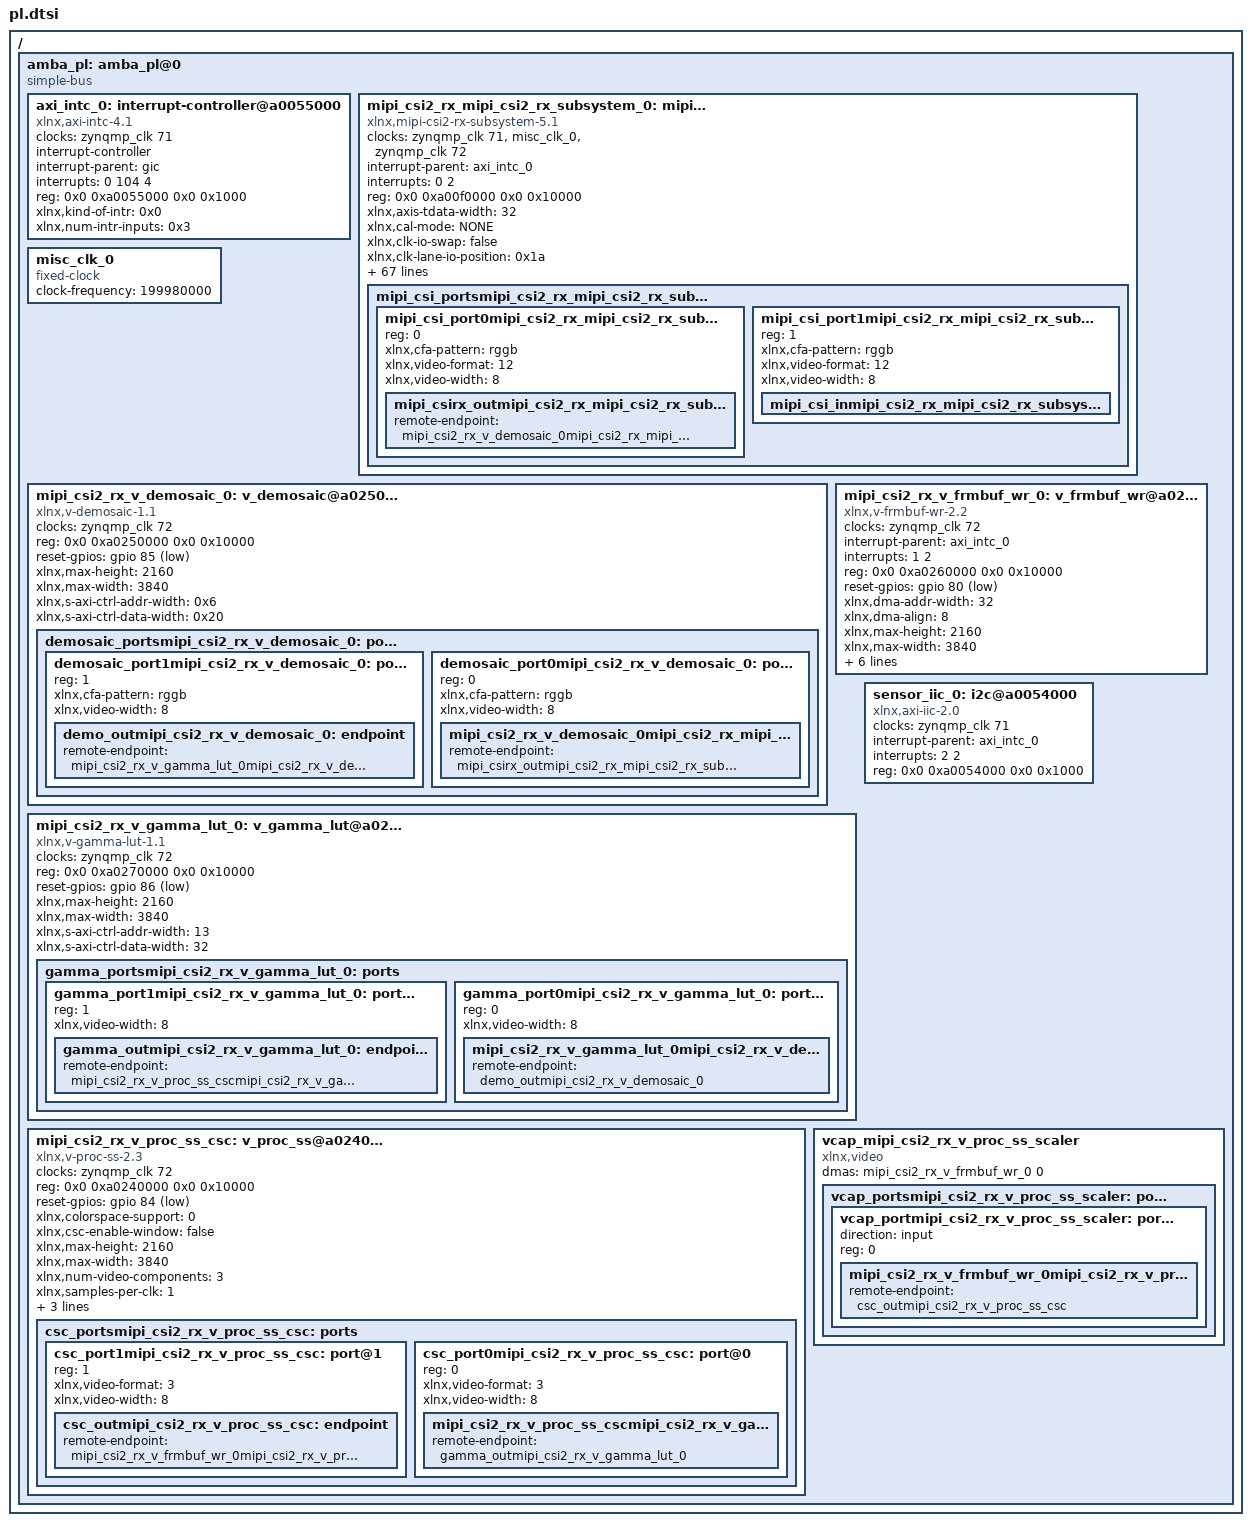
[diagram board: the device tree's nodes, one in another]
/*
 * CAUTION: This file is automatically generated by Xilinx.
 * Version: XSCT 2020.2
 * Today is: Wed Feb  9 18:55:34 2022
 */


/ {
	amba_pl: amba_pl@0 {
		#address-cells = <2>;
		#size-cells = <2>;
		compatible = "simple-bus";
		ranges ;
		axi_intc_0: interrupt-controller@a0055000 {
			#interrupt-cells = <2>;
			clock-names = "s_axi_aclk";
			clocks = <&zynqmp_clk 71>;
			compatible = "xlnx,axi-intc-4.1", "xlnx,xps-intc-1.00.a";
			interrupt-controller ;
			interrupt-names = "irq";
			interrupt-parent = <&gic>;
			interrupts = <0 104 4>;
			reg = <0x0 0xa0055000 0x0 0x1000>;
			xlnx,kind-of-intr = <0x0>;
			xlnx,num-intr-inputs = <0x3>;
		};
		mipi_csi2_rx_mipi_csi2_rx_subsystem_0: mipi_csi2_rx_subsystem@a00f0000 {
			clock-names = "lite_aclk", "dphy_clk_200M", "video_aclk";
			clocks = <&zynqmp_clk 71>, <&misc_clk_0>, <&zynqmp_clk 72>;
			compatible = "xlnx,mipi-csi2-rx-subsystem-5.1";
			interrupt-names = "csirxss_csi_irq";
			interrupt-parent = <&axi_intc_0>;
			interrupts = <0 2>;
			reg = <0x0 0xa00f0000 0x0 0x10000>;
			xlnx,axis-tdata-width = <32>;
			xlnx,cal-mode = "NONE";
			xlnx,clk-io-swap = "false";
			xlnx,clk-lane-io-position = <0x1a>;
			xlnx,clk-lp-io-swap = "false";
			xlnx,csi-en-activelanes = "true";
			xlnx,csi-en-crc = "true";
			xlnx,csi-filter-userdatatype = "true";
			xlnx,csi-opt1-regs = "false";
			xlnx,csi-pxl-format = "RAW10";
			xlnx,csi2rx-dbg = <0x0>;
			xlnx,data-lane0-io-position = <0x2d>;
			xlnx,data-lane1-io-position = <0x20>;
			xlnx,data-lane2-io-position = <0x11>;
			xlnx,data-lane3-io-position = <0x29>;
			xlnx,dl0-io-swap = "false";
			xlnx,dl0-lp-io-swap = "false";
			xlnx,dl1-io-swap = "false";
			xlnx,dl1-lp-io-swap = "false";
			xlnx,dl2-io-swap = "false";
			xlnx,dl2-lp-io-swap = "false";
			xlnx,dl3-io-swap = "false";
			xlnx,dl3-lp-io-swap = "false";
			xlnx,dphy-lanes = <0x4>;
			xlnx,dphy-mode = "SLAVE";
			xlnx,en-7s-linerate-check = "false";
			xlnx,en-active-lanes ;
			xlnx,en-bg0-pin0 = "false";
			xlnx,en-bg0-pin6 = "false";
			xlnx,en-bg1-pin0 = "true";
			xlnx,en-bg1-pin6 = "false";
			xlnx,en-bg2-pin0 = "false";
			xlnx,en-bg2-pin6 = "false";
			xlnx,en-bg3-pin0 = "true";
			xlnx,en-bg3-pin6 = "false";
			xlnx,en-clk300m = "false";
			xlnx,en-cnts-byte-clk = "false";
			xlnx,en-csi-v2-0 = "false";
			xlnx,en-exdesigns = "false";
			xlnx,en-ext-tap = "false";
			xlnx,en-timeout-regs = "false";
			xlnx,en-vcx = "false";
			xlnx,esc-timeout = <0x6400>;
			xlnx,exdes-board = "ZCU102";
			xlnx,exdes-config = "MIPI_Video_Pipe_Camera_to_Display";
			xlnx,exdes-fmc = "LI-IMX274MIPI-FMC V1.0 Single Sensor";
			xlnx,exdesboard-version = "xilinx.com:vck190:part0:2.0";
			xlnx,fifo-rd-en-control = "true";
			xlnx,hs-line-rate = <0x5a0>;
			xlnx,hs-settle-ns = <0x8d>;
			xlnx,hs-timeout = <0x10005>;
			xlnx,idly-group-name = "mipi_csi2rx_idly_group";
			xlnx,idly-tap = <0x1>;
			xlnx,init = <0x186a0>;
			xlnx,int-qor-check = <0x0>;
			xlnx,is-7series = "false";
			xlnx,is-versal = "false";
			xlnx,lprx-disable-extport = <0x0>;
			xlnx,max-lanes = <4>;
			xlnx,mipi-slv-int = <0x0>;
			xlnx,ooc-vid-clk = "6.666";
			xlnx,ppc = <1>;
			xlnx,rcve-alt-deskew-seq = "false";
			xlnx,rcve-deskew-seq = "false";
			xlnx,share-idlyctrl = "false";
			xlnx,stretch-line-rate = <0xdac>;
			xlnx,vc = <4>;
			xlnx,vfb ;
			mipi_csi_portsmipi_csi2_rx_mipi_csi2_rx_subsystem_0: ports {
				#address-cells = <1>;
				#size-cells = <0>;
				mipi_csi_port0mipi_csi2_rx_mipi_csi2_rx_subsystem_0: port@0 {
					/* Fill cfa-pattern=rggb for raw data types, other fields video-format and video-width user needs to fill */
					reg = <0>;
					xlnx,cfa-pattern = "rggb";
					xlnx,video-format = <12>;
					xlnx,video-width = <8>;
					mipi_csirx_outmipi_csi2_rx_mipi_csi2_rx_subsystem_0: endpoint {
						remote-endpoint = <&mipi_csi2_rx_v_demosaic_0mipi_csi2_rx_mipi_csi2_rx_subsystem_0>;
					};
				};
				mipi_csi_port1mipi_csi2_rx_mipi_csi2_rx_subsystem_0: port@1 {
					/* Fill cfa-pattern=rggb for raw data types, other fields video-format,video-width user needs to fill */
					/* User need to add something like remote-endpoint=<&out> under the node csiss_in:endpoint */
					reg = <1>;
					xlnx,cfa-pattern = "rggb";
					xlnx,video-format = <12>;
					xlnx,video-width = <8>;
					mipi_csi_inmipi_csi2_rx_mipi_csi2_rx_subsystem_0: endpoint {
					};
				};
			};
		};
		misc_clk_0: misc_clk_0 {
			#clock-cells = <0>;
			clock-frequency = <199980000>;
			compatible = "fixed-clock";
		};
		mipi_csi2_rx_v_demosaic_0: v_demosaic@a0250000 {
			clock-names = "ap_clk";
			clocks = <&zynqmp_clk 72>;
			compatible = "xlnx,v-demosaic-1.1", "xlnx,v-demosaic";
			reg = <0x0 0xa0250000 0x0 0x10000>;
			reset-gpios = <&gpio 85 1>;
			xlnx,max-height = <2160>;
			xlnx,max-width = <3840>;
			xlnx,s-axi-ctrl-addr-width = <0x6>;
			xlnx,s-axi-ctrl-data-width = <0x20>;
			demosaic_portsmipi_csi2_rx_v_demosaic_0: ports {
				#address-cells = <1>;
				#size-cells = <0>;
				demosaic_port1mipi_csi2_rx_v_demosaic_0: port@1 {
					/* For cfa-pattern=rggb user needs to fill as per BAYER format */
					reg = <1>;
					xlnx,cfa-pattern = "rggb";
					xlnx,video-width = <8>;
					demo_outmipi_csi2_rx_v_demosaic_0: endpoint {
						remote-endpoint = <&mipi_csi2_rx_v_gamma_lut_0mipi_csi2_rx_v_demosaic_0>;
					};
				};
				demosaic_port0mipi_csi2_rx_v_demosaic_0: port@0 {
					/* For cfa-pattern=rggb user needs to fill as per BAYER format */
					reg = <0>;
					xlnx,cfa-pattern = "rggb";
					xlnx,video-width = <8>;
					mipi_csi2_rx_v_demosaic_0mipi_csi2_rx_mipi_csi2_rx_subsystem_0: endpoint {
						remote-endpoint = <&mipi_csirx_outmipi_csi2_rx_mipi_csi2_rx_subsystem_0>;
					};
				};
			};
		};
		mipi_csi2_rx_v_frmbuf_wr_0: v_frmbuf_wr@a0260000 {
			#dma-cells = <1>;
			clock-names = "ap_clk";
			clocks = <&zynqmp_clk 72>;
			compatible = "xlnx,v-frmbuf-wr-2.2", "xlnx,axi-frmbuf-wr-v2.1";
			interrupt-names = "interrupt";
			interrupt-parent = <&axi_intc_0>;
			interrupts = <1 2>;
			reg = <0x0 0xa0260000 0x0 0x10000>;
			reset-gpios = <&gpio 80 1>;
			xlnx,dma-addr-width = <32>;
			xlnx,dma-align = <8>;
			xlnx,max-height = <2160>;
			xlnx,max-width = <3840>;
			xlnx,pixels-per-clock = <1>;
			xlnx,s-axi-ctrl-addr-width = <0x7>;
			xlnx,s-axi-ctrl-data-width = <0x20>;
			xlnx,vid-formats = "bgr888", "xbgr8888", "xrgb8888", "uyvy", "y8", "vuy888", "xvuy8888", "yuyv", "nv12", "nv16";
			xlnx,video-width = <8>;
		};
		mipi_csi2_rx_v_gamma_lut_0: v_gamma_lut@a0270000 {
			clock-names = "ap_clk";
			clocks = <&zynqmp_clk 72>;
			compatible = "xlnx,v-gamma-lut-1.1", "xlnx,v-gamma-lut";
			reg = <0x0 0xa0270000 0x0 0x10000>;
			reset-gpios = <&gpio 86 1>;
			xlnx,max-height = <2160>;
			xlnx,max-width = <3840>;
			xlnx,s-axi-ctrl-addr-width = <13>;
			xlnx,s-axi-ctrl-data-width = <32>;
			gamma_portsmipi_csi2_rx_v_gamma_lut_0: ports {
				#address-cells = <1>;
				#size-cells = <0>;
				gamma_port1mipi_csi2_rx_v_gamma_lut_0: port@1 {
					reg = <1>;
					xlnx,video-width = <8>;
					gamma_outmipi_csi2_rx_v_gamma_lut_0: endpoint {
						remote-endpoint = <&mipi_csi2_rx_v_proc_ss_cscmipi_csi2_rx_v_gamma_lut_0>;
					};
				};
				gamma_port0mipi_csi2_rx_v_gamma_lut_0: port@0 {
					reg = <0>;
					xlnx,video-width = <8>;
					mipi_csi2_rx_v_gamma_lut_0mipi_csi2_rx_v_demosaic_0: endpoint {
						remote-endpoint = <&demo_outmipi_csi2_rx_v_demosaic_0>;
					};
				};
			};
		};
		mipi_csi2_rx_v_proc_ss_csc: v_proc_ss@a0240000 {
			clock-names = "aclk";
			clocks = <&zynqmp_clk 72>;
			compatible = "xlnx,v-proc-ss-2.3", "xlnx,vpss-csc", "xlnx,v-vpss-csc";
			reg = <0x0 0xa0240000 0x0 0x10000>;
			reset-gpios = <&gpio 84 1>;
			xlnx,colorspace-support = <0>;
			xlnx,csc-enable-window = "false";
			xlnx,max-height = <2160>;
			xlnx,max-width = <3840>;
			xlnx,num-video-components = <3>;
			xlnx,samples-per-clk = <1>;
			xlnx,topology = <3>;
			xlnx,use-uram = <0>;
			xlnx,video-width = <8>;
			csc_portsmipi_csi2_rx_v_proc_ss_csc: ports {
				#address-cells = <1>;
				#size-cells = <0>;
				csc_port1mipi_csi2_rx_v_proc_ss_csc: port@1 {
					/* For xlnx,video-format user needs to fill as per their requirement */
					reg = <1>;
					xlnx,video-format = <3>;
					xlnx,video-width = <8>;
					csc_outmipi_csi2_rx_v_proc_ss_csc: endpoint {
						remote-endpoint = <&mipi_csi2_rx_v_frmbuf_wr_0mipi_csi2_rx_v_proc_ss_scaler>;
					};
				};
				csc_port0mipi_csi2_rx_v_proc_ss_csc: port@0 {
					/* For xlnx,video-format user needs to fill as per their requirement */
					reg = <0>;
					xlnx,video-format = <3>;
					xlnx,video-width = <8>;
					mipi_csi2_rx_v_proc_ss_cscmipi_csi2_rx_v_gamma_lut_0: endpoint {
						remote-endpoint = <&gamma_outmipi_csi2_rx_v_gamma_lut_0>;
					};
				};
			};
		};
		sensor_iic_0: i2c@a0054000 {
			#address-cells = <1>;
			#size-cells = <0>;
			clock-names = "s_axi_aclk";
			clocks = <&zynqmp_clk 71>;
			compatible = "xlnx,axi-iic-2.0", "xlnx,xps-iic-2.00.a";
			interrupt-names = "iic2intc_irpt";
			interrupt-parent = <&axi_intc_0>;
			interrupts = <2 2>;
			reg = <0x0 0xa0054000 0x0 0x1000>;
		};
		vcap_mipi_csi2_rx_v_proc_ss_scaler {
			compatible = "xlnx,video";
			dma-names = "port0";
			dmas = <&mipi_csi2_rx_v_frmbuf_wr_0 0>;
			vcap_portsmipi_csi2_rx_v_proc_ss_scaler: ports {
				#address-cells = <1>;
				#size-cells = <0>;
				vcap_portmipi_csi2_rx_v_proc_ss_scaler: port@0 {
					direction = "input";
					reg = <0>;
					mipi_csi2_rx_v_frmbuf_wr_0mipi_csi2_rx_v_proc_ss_scaler: endpoint {
						remote-endpoint = <&csc_outmipi_csi2_rx_v_proc_ss_csc>;
					};
				};
			};
		};
	};
};
